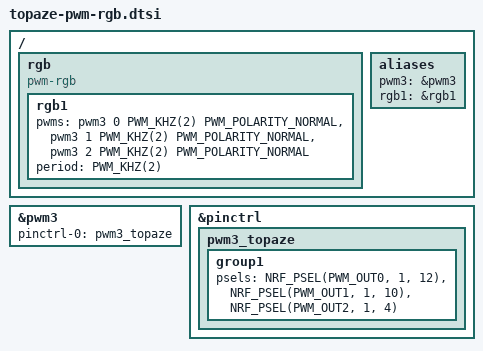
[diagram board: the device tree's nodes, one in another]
/* ============================================================
 * This file is the overlay DTS for topaze that define the PWM
 * peripheral
 *
 * We describe here the peripherals configuration, and so on...
 *
 * l.heywang
 * 01/03/2025
 *
 * ============================================================
 */

// ============================================================
// PWM
// ============================================================
// Peripheral configuration
&pwm3 {
    status = "okay";
    pinctrl-0 = <&pwm3_topaze>;
    pinctrl-names = "default";
};

// Pin muxing configuration
&pinctrl {
    pwm3_topaze: pwm3_topaze {
        group1 {
            psels = <NRF_PSEL(PWM_OUT0, 1, 12)>,
                    <NRF_PSEL(PWM_OUT1, 1, 10)>,
                    <NRF_PSEL(PWM_OUT2, 1, 4)>;
        };
    };
};

// Operating parameters configuration
/{
    rgb {
        compatible = "pwm-rgb";
        rgb1: rgb1 {
            pwms = <&pwm3 0 PWM_KHZ(2) PWM_POLARITY_NORMAL>,
                   <&pwm3 1 PWM_KHZ(2) PWM_POLARITY_NORMAL>,
                   <&pwm3 2 PWM_KHZ(2) PWM_POLARITY_NORMAL>;
            period = <PWM_KHZ(2)>;
        };
    };
};

// Set aliases for this module
/{
    aliases {
        pwm3 = &pwm3;
        rgb1 = &rgb1;
    };
};








